# PIC32MX764F128L register map
Vendor: Microchip
Registers are 32-bit, read-write, reset 0x0 unless marked. A register's access mark holds for its fields unless they carry their own. Addresses are absolute, and some are shared; only a register's first bit layout is shown; [hi:lo] are bit positions.

## I2C2
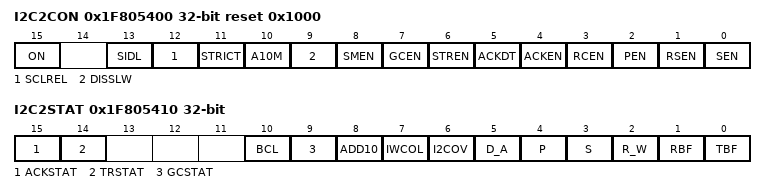
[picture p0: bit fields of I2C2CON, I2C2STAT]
0x1F805400 I2C2CON reset 0x1000
  [15] ON, [13] SIDL, [12] SCLREL, [11] STRICT, [10] A10M, [9] DISSLW, [8] SMEN, [7] GCEN, [6] STREN, [5] ACKDT, [4] ACKEN, [3] RCEN, [2] PEN, [1] RSEN, [0] SEN
0x1F805410 I2C2STAT
  [15] ACKSTAT ro
  [14] TRSTAT ro
  [10] BCL — (can only be cleared)
  [9] GCSTAT ro
  [8] ADD10 ro
  [7] IWCOL — (can only be cleared)
  [6] I2COV — (can only be cleared)
  [5] D_A ro
  [4] P — (can only be cleared)
  [3] S — (can only be cleared)
  [2] R_W ro
  [1] RBF ro
  [0] TBF ro
0x1F805420 I2C2ADD
  [9:0] I2CADD
0x1F805430 I2C2MSK
  [9:0] I2CMSK
0x1F805440 I2C2BRG
  [11:0] I2CBRG
0x1F805450 I2C2TRN
  [7:0] I2CTRN
0x1F805460 I2C2RCV
  [7:0] I2CRCV

## SPI3
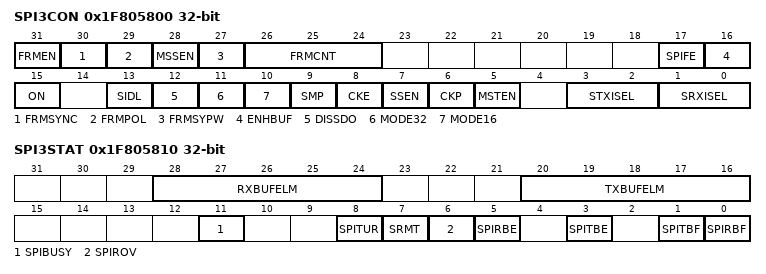
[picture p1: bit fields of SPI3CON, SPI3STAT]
0x1F805800 SPI3CON
  [31] FRMEN, [30] FRMSYNC, [29] FRMPOL, [28] MSSEN, [27] FRMSYPW, [26:24] FRMCNT, [17] SPIFE, [16] ENHBUF, [15] ON, [13] SIDL, [12] DISSDO, [11] MODE32, [10] MODE16, [9] SMP, [8] CKE, [7] SSEN, [6] CKP, [5] MSTEN, [3:2] STXISEL, [1:0] SRXISEL
0x1F805810 SPI3STAT ro
  [28:24] RXBUFELM, [20:16] TXBUFELM, [11] SPIBUSY, [8] SPITUR, [7] SRMT, [6] SPIROV, [5] SPIRBE, [3] SPITBE, [1] SPITBF, [0] SPIRBF
0x1F805820 SPI3BUF reset not defined — (power-on value xxxxxxxxxxxxxxxxxxxxxxxxxxxxxxxx)
0x1F805830 SPI3BRG
  [8:0] SPI3BRG

## SPI2
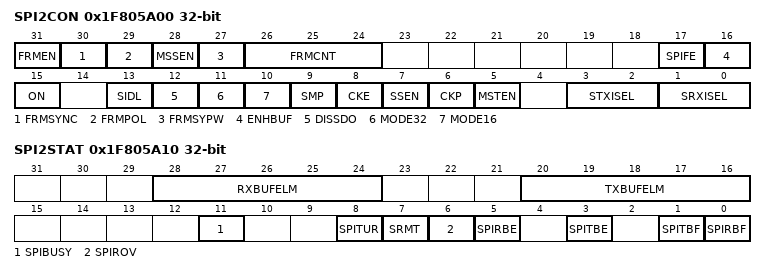
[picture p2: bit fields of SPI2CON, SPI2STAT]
0x1F805A00 SPI2CON
  [31] FRMEN, [30] FRMSYNC, [29] FRMPOL, [28] MSSEN, [27] FRMSYPW, [26:24] FRMCNT, [17] SPIFE, [16] ENHBUF, [15] ON, [13] SIDL, [12] DISSDO, [11] MODE32, [10] MODE16, [9] SMP, [8] CKE, [7] SSEN, [6] CKP, [5] MSTEN, [3:2] STXISEL, [1:0] SRXISEL
0x1F805A10 SPI2STAT ro
  [28:24] RXBUFELM, [20:16] TXBUFELM, [11] SPIBUSY, [8] SPITUR, [7] SRMT, [6] SPIROV, [5] SPIRBE, [3] SPITBE, [1] SPITBF, [0] SPIRBF
0x1F805A20 SPI2BUF reset not defined — (power-on value xxxxxxxxxxxxxxxxxxxxxxxxxxxxxxxx)
0x1F805A30 SPI2BRG
  [8:0] SPI2BRG

## SPI4
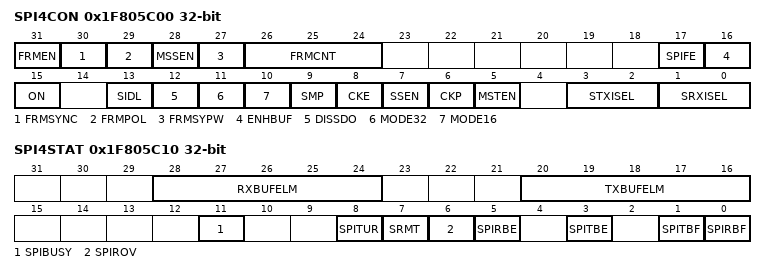
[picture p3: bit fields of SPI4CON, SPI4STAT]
0x1F805C00 SPI4CON
  [31] FRMEN, [30] FRMSYNC, [29] FRMPOL, [28] MSSEN, [27] FRMSYPW, [26:24] FRMCNT, [17] SPIFE, [16] ENHBUF, [15] ON, [13] SIDL, [12] DISSDO, [11] MODE32, [10] MODE16, [9] SMP, [8] CKE, [7] SSEN, [6] CKP, [5] MSTEN, [3:2] STXISEL, [1:0] SRXISEL
0x1F805C10 SPI4STAT ro
  [28:24] RXBUFELM, [20:16] TXBUFELM, [11] SPIBUSY, [8] SPITUR, [7] SRMT, [6] SPIROV, [5] SPIRBE, [3] SPITBE, [1] SPITBF, [0] SPIRBF
0x1F805C20 SPI4BUF reset not defined — (power-on value xxxxxxxxxxxxxxxxxxxxxxxxxxxxxxxx)
0x1F805C30 SPI4BRG
  [8:0] SPI4BRG

## SPI1
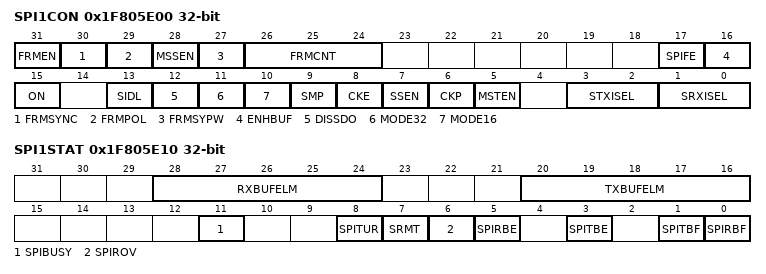
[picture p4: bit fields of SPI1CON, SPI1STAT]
0x1F805E00 SPI1CON
  [31] FRMEN, [30] FRMSYNC, [29] FRMPOL, [28] MSSEN, [27] FRMSYPW, [26:24] FRMCNT, [17] SPIFE, [16] ENHBUF, [15] ON, [13] SIDL, [12] DISSDO, [11] MODE32, [10] MODE16, [9] SMP, [8] CKE, [7] SSEN, [6] CKP, [5] MSTEN, [3:2] STXISEL, [1:0] SRXISEL
0x1F805E10 SPI1STAT ro
  [28:24] RXBUFELM, [20:16] TXBUFELM, [11] SPIBUSY, [8] SPITUR, [7] SRMT, [6] SPIROV, [5] SPIRBE, [3] SPITBE, [1] SPITBF, [0] SPIRBF
0x1F805E20 SPI1BUF reset not defined — (power-on value xxxxxxxxxxxxxxxxxxxxxxxxxxxxxxxx)
0x1F805E30 SPI1BRG
  [8:0] SPI1BRG

## UART1
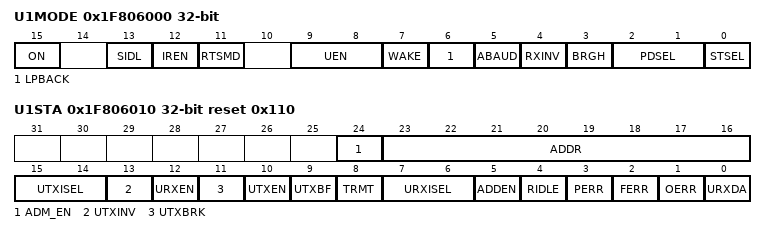
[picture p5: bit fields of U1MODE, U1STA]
0x1F806000 U1MODE
  [15] ON, [13] SIDL, [12] IREN, [11] RTSMD, [9:8] UEN, [7] WAKE, [6] LPBACK, [5] ABAUD, [4] RXINV, [3] BRGH, [2:1] PDSEL, [0] STSEL
0x1F806010 U1STA reset 0x110
  [24] ADM_EN
  [23:16] ADDR
  [15:14] UTXISEL
  [13] UTXINV
  [12] URXEN
  [11] UTXBRK
  [10] UTXEN
  [9] UTXBF ro
  [8] TRMT ro
  [7:6] URXISEL
  [5] ADDEN
  [4] RIDLE ro
  [3] PERR ro
  [2] FERR ro
  [1] OERR — (can only be cleared)
  [0] URXDA ro
0x1F806020 U1TXREG reset not defined — (power-on value -----------------------xxxxxxxxx)
  [8:0] U1TXREG
0x1F806030 U1RXREG ro
  [8:0] U1RXREG
0x1F806040 U1BRG
  [15:0] BRG

## UART4
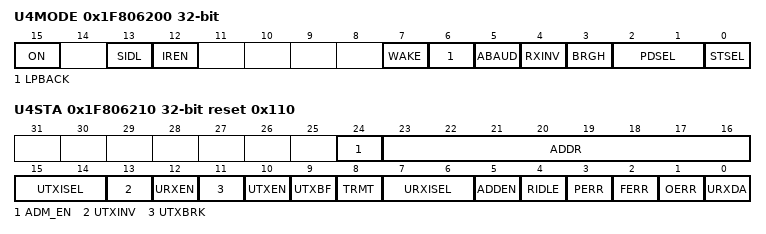
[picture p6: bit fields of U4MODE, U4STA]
0x1F806200 U4MODE
  [15] ON, [13] SIDL, [12] IREN, [7] WAKE, [6] LPBACK, [5] ABAUD, [4] RXINV, [3] BRGH, [2:1] PDSEL, [0] STSEL
0x1F806210 U4STA reset 0x110
  [24] ADM_EN
  [23:16] ADDR
  [15:14] UTXISEL
  [13] UTXINV
  [12] URXEN
  [11] UTXBRK
  [10] UTXEN
  [9] UTXBF ro
  [8] TRMT ro
  [7:6] URXISEL
  [5] ADDEN
  [4] RIDLE ro
  [3] PERR ro
  [2] FERR ro
  [1] OERR — (can only be cleared)
  [0] URXDA ro
0x1F806220 U4TXREG reset not defined — (power-on value -----------------------xxxxxxxxx)
  [8:0] U4TXREG
0x1F806230 U4RXREG ro
  [8:0] U4RXREG
0x1F806240 U4BRG
  [15:0] BRG
